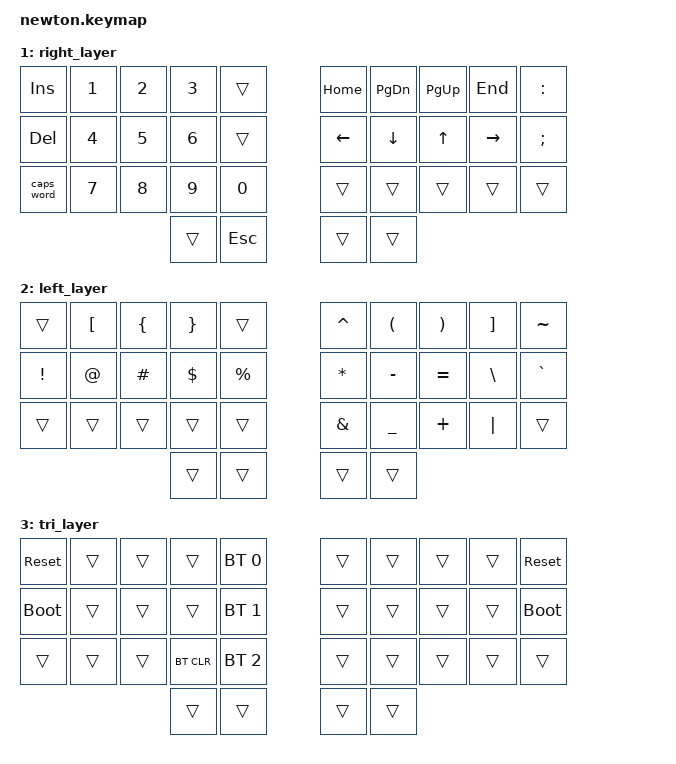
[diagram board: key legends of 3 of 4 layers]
// Copyright (c) 2022 The ZMK Contributors
// SPDX-License-Identifier: MIT

#include <behaviors.dtsi>
#include <dt-bindings/zmk/keys.h>
#include <dt-bindings/zmk/bt.h>
#include <dt-bindings/zmk/rgb.h>


/ {
	behaviors {
		ht: hold_tap {
			compatible = "zmk,behavior-hold-tap";
			#binding-cells = <2>;
			flavor = "tap-preferred";
			tapping-term-ms = <220>;
			quick-tap-ms = <150>;
			require-prior-idle-ms = <100>;
			bindings = <&kp>, <&kp>;
		};

		rgb_encoder: rgb_encoder {
			compatible = "zmk,behavior-sensor-rotate";
			#sensor-binding-cells = <0>;
			bindings = <&rgb_ug RGB_BRI>, <&rgb_ug RGB_BRD>;
		};

		vol_encoder: vol_encoder {
			compatible = "zmk,behavior-sensor-rotate";
			#sensor-binding-cells = <0>;
			bindings = <&rgb_ug RGB_BRI>, <&rgb_ug RGB_BRD>;
		};

	};

	conditional_layers {
		compatible = "zmk,conditional-layers";
		tri_layer {
			if-layers = <1 2>;
			then-layer = <3>;
		};

	};

	keymap {
		compatible = "zmk,keymap";
		default_layer {
			bindings = <
			&kp Q      &kp W       &kp E     &kp R    &kp T      &kp Y      &kp U         &kp I      &kp O    &kp P
			&kp A      &kp S       &kp D     &kp F    &kp G      &kp H      &kp J         &kp K      &kp L    &kp L
			&kp Z      &kp X       &kp C     &kp V    &kp B      &kp N      &kp M         &kp COMMA  &kp DOT  &kp FSLH
			&kp N1     &kp N2      &kp N3    &kp N4   &kp N5     &kp N6     
			>;
			sensor-bindings = <&inc_dec_kp C_VOL_UP C_VOL_DN &inc_dec_kp C_VOL_UP C_VOL_DN>;
		};


		right_layer {
			bindings = <
			//╭──────────┬──────────┬──────────┬──────────┬──────────╮   ╭──────────┬──────────┬──────────┬──────────┬──────────╮
			//│ INSERT   │  1       │  2       │  3       │          │   │ HOME     │ PAGE DN  │ PAGE UP  │ END      │  :       │
			&kp INS    &kp N1     &kp N2     &kp N3     &trans         &kp HOME   &kp PG_DN  &kp PG_UP  &kp END    &kp COLON
			//├──────────┼──────────┼──────────┼──────────┼──────────┤   ├──────────┼──────────┼──────────┼──────────┼──────────┤
			//│ DELETE   │  4       │  5       │  6       │          │   │ LEFT     │ DOWN     │ UP       │ RIGHT    │  ;       │
			&kp DEL    &kp N4     &kp N5     &kp N6     &trans         &kp LEFT   &kp DOWN   &kp UP   &kp RIGHT   &kp SEMI
			//├──────────┼──────────┼──────────┼──────────┼──────────┤   ├──────────┼──────────┼──────────┼──────────┼──────────┤
			//│ CAPS     │  7       │  8       │  9       │  0       │   │          │          │          │          │          │
			&caps_word  &kp N7     &kp N8     &kp N9     &kp N0         &trans     &trans     &trans     &trans     &trans
			//╰──────────┴──────────┴──────────┼──────────┼──────────┤   ├──────────┼──────────┼──────────┴──────────┴──────────╯
			&trans     &kp ESC        &trans     &trans
			//                                 ╰──────────┴──────────╯   ╰──────────┴──────────╯
			>;
			sensor-bindings = <&inc_dec_kp C_VOL_UP C_VOL_DN>;
		};

		left_layer {
			bindings = <
			//╭──────────┬──────────┬──────────┬──────────┬──────────╮   ╭──────────┬──────────┬──────────┬──────────┬──────────╮
			//│          │  [       │  {       │  }       │          │   │  ^       │  (       │  )       │  ]       │  ~       │
			&trans     &kp LBKT   &kp LBRC   &kp RBRC   &trans         &kp CARET  &kp LPAR   &kp RPAR   &kp RBKT   &kp TILDE
			//├──────────┼──────────┼──────────┼──────────┼──────────┤   ├──────────┼──────────┼──────────┼──────────┼──────────┤
			//│  !       │  @       │  #       │  $       │  %       │   │  *       │  -       │  =       │  \       │  `       │
			&kp EXCL   &kp AT     &kp HASH   &kp DLLR   &kp PRCNT      &kp ASTRK  &kp MINUS  &kp EQUAL  &kp BSLH   &kp GRAVE
			//├──────────┼──────────┼──────────┼──────────┼──────────┤   ├──────────┼──────────┼──────────┼──────────┼──────────┤
			//│          │          │          │          │          │   │  &       │  _       │  +       │  │       │          │
			&trans     &trans     &trans     &trans     &trans         &kp AMPS   &kp UNDER  &kp PLUS   &kp PIPE   &trans
			//╰──────────┴──────────┴──────────┼──────────┼──────────┤   ├──────────┼──────────┼──────────┴──────────┴──────────╯
			&trans     &trans         &trans     &trans
			//                                 ╰──────────┴──────────╯   ╰──────────┴──────────╯
			>;
			sensor-bindings = <&inc_dec_kp C_VOL_UP C_VOL_DN>;
		};

		tri_layer {
			bindings = <
			//╭──────────┬──────────┬──────────┬──────────┬──────────╮   ╭──────────┬──────────┬──────────┬──────────┬──────────╮
			//│ RESET    │          │          │          │PROFILE 0 │   │          │          │          │          │  RESET   │
			&sys_reset  &trans     &trans     &trans    &bt BT_SEL 0    &trans     &trans     &trans     &trans    &sys_reset
			//├──────────┼──────────┼──────────┼──────────┼──────────┤   ├──────────┼──────────┼──────────┼──────────┼──────────┤
			//│BOOTLOADER│          │          │          │PROFILE 1 │   │          │          │          │          │BOOTLOADER│
			&bootloader  &trans     &trans     &trans    &bt BT_SEL 1    &trans     &trans     &trans     &trans    &bootloader
			//├──────────┼──────────┼──────────┼──────────┼──────────┤   ├──────────┼──────────┼──────────┼──────────┼──────────┤
			//│          │          │          │ CLEAR BT │PROFILE 2 │   │          │          │          │          │          │
			&trans     &trans     &trans    &bt BT_CLR &bt BT_SEL 2    &trans     &trans     &trans     &trans     &trans
			//╰──────────┴──────────┴──────────┼──────────┼──────────┤   ├──────────┼──────────┼──────────┴──────────┴──────────╯
			&trans     &trans         &trans     &trans
			//                                 ╰──────────┴──────────╯   ╰──────────┴──────────╯
			>;
			sensor-bindings = <&inc_dec_kp C_VOL_UP C_VOL_DN>;
		};
	};
};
